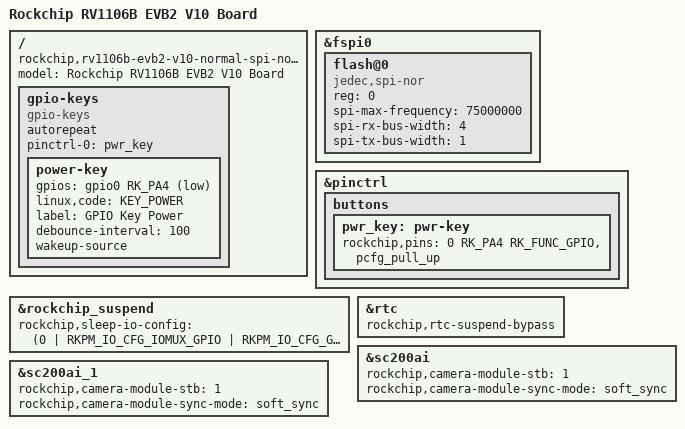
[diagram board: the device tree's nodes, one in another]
// SPDX-License-Identifier: (GPL-2.0+ OR MIT)
/*
 * Copyright (c) 2026 Rockchip Electronics Co., Ltd.
 */
/dts-v1/;
#include "rv1106b.dtsi"
#include "rv1106b-amp.dtsi"
#include "rv1106b-evb2-v10.dtsi"
#include "rv1106b-evb2-dual-cam.dtsi"

/ {
	model = "Rockchip RV1106B EVB2 V10 Board";
	compatible = "rockchip,rv1106b-evb2-v10-normal-spi-nor-dual-cam", "rockchip,rv1106b";

	gpio-keys {
		compatible = "gpio-keys";
		autorepeat;
		pinctrl-names = "default";
		pinctrl-0 = <&pwr_key>;
		power-key {
			gpios = <&gpio0 RK_PA4 GPIO_ACTIVE_LOW>;
			linux,code = <KEY_POWER>;
			label ="GPIO Key Power";
			debounce-interval = <100>;
			wakeup-source;
			/* gpio-key,wakeup; */
		};
	};
};

&fspi0 {
	status = "okay";

	flash@0 {
		compatible = "jedec,spi-nor";
		reg = <0>;
		spi-max-frequency = <75000000>;
		spi-rx-bus-width = <4>;
		spi-tx-bus-width = <1>;
	};
};

&pinctrl {
	buttons {
		pwr_key: pwr-key {
			rockchip,pins = <0 RK_PA4 RK_FUNC_GPIO &pcfg_pull_up>;
		};
	};
};


&rockchip_suspend {
	status = "okay";

	rockchip,sleep-io-config = <
		/* pmic_sleep */
		(0
		| RKPM_IO_CFG_IOMUX_GPIO
		| RKPM_IO_CFG_GPIO_DIR_INPUT
		| RKPM_IO_CFG_PULL_DOWN
		| RKPM_IO_CFG_ID(0)
		)
		(0
		| RKPM_IO_CFG_IOMUX_GPIO
		| RKPM_IO_CFG_GPIO_DIR_INPUT
		| RKPM_IO_CFG_PULL_NONE
		| RKPM_IO_CFG_ID(1)
		)
		(0
		| RKPM_IO_CFG_IOMUX_GPIO
		| RKPM_IO_CFG_GPIO_DIR_INPUT
		| RKPM_IO_CFG_PULL_NONE
		| RKPM_IO_CFG_ID(2)
		)
		(0
		| RKPM_IO_CFG_IOMUX(1)
		| RKPM_IO_CFG_PULL_NONE
		| RKPM_IO_CFG_ID(3)
		)
		(0
		| RKPM_IO_CFG_IOMUX_GPIO
		| RKPM_IO_CFG_GPIO_DIR_INPUT
		| RKPM_IO_CFG_PULL_UP
		| RKPM_IO_CFG_ID(4)
		)
		(0
		| RKPM_IO_CFG_IOMUX_GPIO
		| RKPM_IO_CFG_GPIO_DIR_INPUT
		| RKPM_IO_CFG_PULL_DOWN
		| RKPM_IO_CFG_ID(5)
		)
		(0
		| RKPM_IO_CFG_IOMUX_GPIO
		| RKPM_IO_CFG_GPIO_DIR_INPUT
		| RKPM_IO_CFG_PULL_DOWN
		| RKPM_IO_CFG_ID(6)
		)
	>;
};

&rtc {
	rockchip,rtc-suspend-bypass;
	status = "okay";
};

&sc200ai {
	rockchip,camera-module-stb = <1>;
	rockchip,camera-module-sync-mode = "soft_sync";
};

&sc200ai_1 {
	rockchip,camera-module-stb = <1>;
	rockchip,camera-module-sync-mode = "soft_sync";
};
